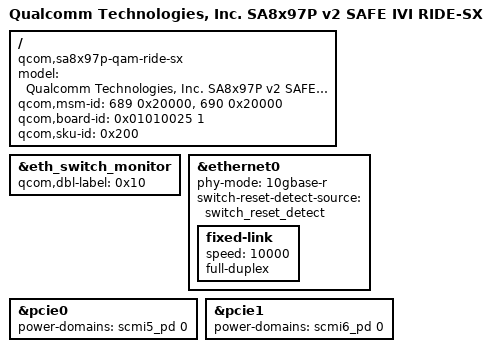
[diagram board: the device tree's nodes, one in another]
// SPDX-License-Identifier: BSD-3-Clause
/*
 * Copyright (c) Qualcomm Technologies, Inc. and/or its subsidiaries.
 */

/dts-v1/;

#include "sa8x97p.dtsi"
#include "sa8x97p-v2.dtsi"
#include "sa8797p.dtsi"
#include "sa8x97p-safe.dtsi"

/ {
	model = "Qualcomm Technologies, Inc. SA8x97P v2 SAFE IVI RIDE-SX";
	compatible = "qcom,sa8x97p-qam-ride-sx", "qcom,safe-ivi", "qcom,sa8x97p-qam", "qcom,sa8797p";
	qcom,msm-id = <689 0x20000>, <690 0x20000>;
	qcom,board-id = <0x01010025 1>;
	qcom,sku-id = <0x200>;
};

&eth_switch_monitor {
	status = "okay";
	qcom,dbl-label = <0x10>;
};

&ethernet0 {
	phy-mode = "10gbase-r";
	switch-reset-detect-source = <&switch_reset_detect>;

	fixed-link {
		status = "okay";
		speed = <10000>;
		full-duplex;
	};
};

&pcie0 {
	power-domains = <&scmi5_pd 0>;
	power-domain-names = "power";
	status = "okay";
};

&pcie1 {
	power-domains = <&scmi6_pd 0>;
	power-domain-names = "power";
	status = "okay";
};
